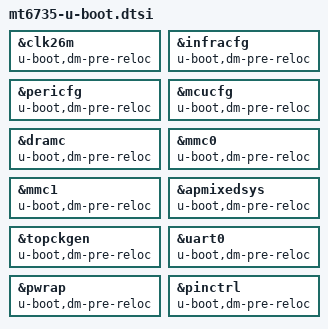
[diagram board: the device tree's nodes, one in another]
// SPDX-License-Identifier: GPL-2.0

#include "mt6735.dtsi"

&clk26m {
    u-boot,dm-pre-reloc;
};

&infracfg {
    u-boot,dm-pre-reloc;
};

&pericfg {
    u-boot,dm-pre-reloc;
};

&mcucfg {
    u-boot,dm-pre-reloc;
};

&dramc {
    u-boot,dm-pre-reloc;
};

&mmc0 {
    u-boot,dm-pre-reloc;
};

&mmc1 {
    u-boot,dm-pre-reloc;
};

&apmixedsys {
    u-boot,dm-pre-reloc;
};

&topckgen {
    u-boot,dm-pre-reloc;
};

&uart0 {
    u-boot,dm-pre-reloc;
};

&pwrap {
    u-boot,dm-pre-reloc;
};

&pinctrl {
    u-boot,dm-pre-reloc;
};

